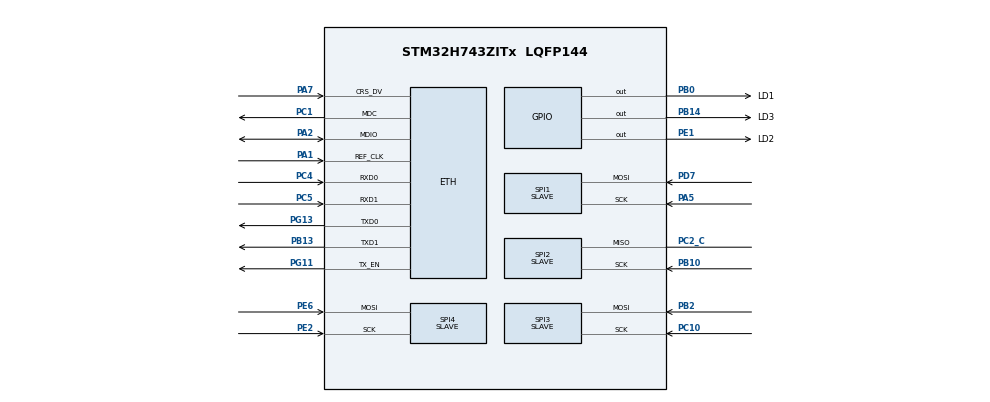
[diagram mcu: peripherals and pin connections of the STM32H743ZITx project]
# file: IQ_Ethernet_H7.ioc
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Mcu.Family=STM32H7
PD7.Mode=RX_Only_Simplex_Unidirect_Slave
LWIP0.BSP.STBoard=false
RCC.CortexFreq_Value=480000000
SPI3.Direction=SPI_DIRECTION_2LINES_RXONLY
SPI4.VirtualType=VM_SLAVE
SPI3.VirtualType=VM_SLAVE
SPI1.VirtualType=VM_SLAVE
SPI2.VirtualType=VM_SLAVE
PB10.Mode=Simplex_Bidirectional_Slave
RCC.HPRE=RCC_HCLK_DIV2
PH0-OSC_IN\ (PH0).Signal=RCC_OSC_IN
RCC.PLL2_VCI_Range-AdvancedSettings=RCC_PLL2VCIRANGE_0
PC10.Signal=SPI3_SCK
PB14.GPIO_Label=LD3
CORTEX_M7.TypeExtField-Cortex_Memory_Protection_Unit_Region0_Settings=MPU_TEX_LEVEL1
RCC.PLLFRACN=0
SPI4.Direction=SPI_DIRECTION_2LINES_RXONLY
PB0.GPIO_Label=LD1
RCC.PLL2FRACN=0
PC5.Mode=RMII
PB13.Signal=ETH_TXD1
PG13.Signal=ETH_TXD0
PG11.Signal=ETH_TX_EN
RCC.SYSCLKSource=RCC_SYSCLKSOURCE_PLLCLK
ProjectManager.StackSize=0x400
LWIP.NETMASK_ADDRESS=255.255.255.000
RCC.SPI123CLockSelection=RCC_SPI123CLKSOURCE_PLL2
CORTEX_M7.Enable-Cortex_Memory_Protection_Unit_Region0_Settings=MPU_REGION_ENABLE
SPI4.Mode=SPI_MODE_SLAVE
SPI1.Direction=SPI_DIRECTION_2LINES_RXONLY
RCC.HCLKFreq_Value=240000000
PE2.Mode=RX_Only_Simplex_Unidirect_Slave
PE1.Signal=GPIO_Output
PC2_C.Signal=SPI2_MISO
SPI3.DataSize=SPI_DATASIZE_8BIT
LWIP.LWIP_RAM_HEAP_POINTER=0x30002000
PH1-OSC_OUT\ (PH1).Mode=HSE-External-Oscillator
PB2.Signal=SPI3_MOSI
RCC.DIVM3=25
RCC.DIVM2=2
RCC.DIVM1=5
LWIP.MEM_SIZE=10*1024
RCC.PLL1_VCI_Range-AdvancedSettings=RCC_PLL1VCIRANGE_0
SPI1.DataSize=SPI_DATASIZE_8BIT
PE2.Signal=SPI4_SCK
PG13.Mode=RMII
RCC.PLL2_VCO_SEL-AdvancedSettings=RCC_PLL2VCOMEDIUM
LWIP0.BSP.solution=LAN8742
CORTEX_M7.DisableExec-Cortex_Memory_Protection_Unit_Region0_Settings=MPU_INSTRUCTION_ACCESS_DISABLE
RCC.APB3Freq_Value=120000000
LWIP0.BSP.component=LAN8742
Mcu.Package=LQFP144
SPI2.Mode=SPI_MODE_SLAVE
RCC.PLL3FRACN=0
RCC.D1PPRE=RCC_APB3_DIV2
SPI3.Mode=SPI_MODE_SLAVE
SPI2.CLKPhase=SPI_PHASE_2EDGE
RCC.APB4Freq_Value=120000000
ETH.RxBuffAddress=0x30000100
SPI2.Direction=SPI_DIRECTION_1LINE
PC5.Signal=ETH_RXD1
PB13.Mode=RMII
PH0-OSC_IN\ (PH0).Mode=HSE-External-Oscillator
PC4.Mode=RMII
LWIP.IP_ADDRESS=192.168.000.015
PA5.Mode=RX_Only_Simplex_Unidirect_Slave
RCC.PLLSourceVirtual=RCC_PLLSOURCE_HSE
CORTEX_M7.CPU_ICache=Enabled
PA7.Mode=RMII
LWIP0.BSP.i2caddr=0
SPI4.DataSize=SPI_DATASIZE_8BIT
PC4.Signal=ETH_RXD0
PC10.Mode=RX_Only_Simplex_Unidirect_Slave
PD7.Signal=SPI1_MOSI
RCC.D2PPRE2=RCC_APB2_DIV2
RCC.D2PPRE1=RCC_APB1_DIV2
SPI1.CLKPhase=SPI_PHASE_2EDGE
LWIP.LWIP_DHCP=0
PH1-OSC_OUT\ (PH1).Signal=RCC_OSC_OUT
LWIP.GATEWAY_ADDRESS=192.168.000.001
VP_LWIP_VS_Enabled.Mode=Enabled
CORTEX_M7.MPU_Control=MPU_PRIVILEGED_DEFAULT
ProjectManager.TargetToolchain=STM32CubeIDE
RCC.DIVN3=130
RCC.DIVN2=12
RCC.DIVN1=192
PC2_C.Mode=Simplex_Bidirectional_Slave
CORTEX_M7.BaseAddress-Cortex_Memory_Protection_Unit_Region0_Settings=0x30000000
LWIP0.BSP.instance=LAN8742
RCC.USBFreq_Value=480000000
LWIP0.BSP.api=BSP_COMPONENT_DRIVER
PA1.Signal=ETH_REF_CLK
PB10.Signal=SPI2_SCK
PB14.Signal=GPIO_Output
PA5.Signal=SPI1_SCK
board=custom
SPI3.CLKPhase=SPI_PHASE_2EDGE
PE1.GPIO_Label=LD2
RCC.APB2Freq_Value=120000000
PA1.Mode=RMII
PE6.Mode=RX_Only_Simplex_Unidirect_Slave
SPI1.Mode=SPI_MODE_SLAVE
CORTEX_M7.IsShareable-Cortex_Memory_Protection_Unit_Region0_Settings=MPU_ACCESS_SHAREABLE
RCC.ADCFreq_Value=75000000
CORTEX_M7.AccessPermission-Cortex_Memory_Protection_Unit_Region0_Settings=MPU_REGION_FULL_ACCESS
PE6.Signal=SPI4_MOSI
Mcu.Name=STM32H743ZITx
CORTEX_M7.Size-Cortex_Memory_Protection_Unit_Region0_Settings=MPU_REGION_SIZE_32KB
PA2.Signal=ETH_MDIO
RCC.PLL3_VCO_SEL-AdvancedSettings=RCC_PLL3VCOMEDIUM
RCC.SYSCLKFreq_VALUE=480000000
ETH.MediaInterface=HAL_ETH_RMII_MODE
LWIP.BSP.number=1
PB2.Mode=RX_Only_Simplex_Unidirect_Slave
PG11.Mode=RMII
ProjectManager.HeapSize=0x200
LWIP.Version=v2.1.2_Cube
SPI4.CLKPhase=SPI_PHASE_2EDGE
NVIC.PriorityGroup=NVIC_PRIORITYGROUP_4
PA2.Mode=RMII
RCC.D3PPRE=RCC_APB4_DIV2
SPI2.DataSize=SPI_DATASIZE_8BIT
ETH.RxDescAddress=0x30000000
CORTEX_M7.CPU_DCache=Enabled
LWIP0.BSP.name=Driver_PHY
RCC.APB1Freq_Value=120000000
PB0.Signal=GPIO_Output
PC1.Signal=ETH_MDC
PC1.Mode=RMII
PA7.Signal=ETH_CRS_DV
ETH.TxDescAddress=0x30000080

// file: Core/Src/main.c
/* USER CODE BEGIN Header */
/**
  ******************************************************************************
  * @file           : main.c
  * @brief          : Main program body
  ******************************************************************************
  * @attention
  *
  * <h2><center>&copy; Copyright (c) 2022 STMicroelectronics.
  * All rights reserved.</center></h2>
  *
  * This software component is licensed by ST under BSD 3-Clause license,
  * the "License"; You may not use this file except in compliance with the
  * License. You may obtain a copy of the License at:
  *                        opensource.org/licenses/BSD-3-Clause
  *
  ******************************************************************************
  */
/* USER CODE END Header */
#include "main.h"
#include "lwip.h"

SPI_HandleTypeDef hspi1;
SPI_HandleTypeDef hspi2;
SPI_HandleTypeDef hspi3;
SPI_HandleTypeDef hspi4;

/* USER CODE BEGIN PV */
extern struct netif  gnetif;
/* USER CODE END PV */

void SystemClock_Config(void);
void PeriphCommonClock_Config(void);
static void MPU_Config(void);
static void MX_GPIO_Init(void);
static void MX_SPI1_Init(void);
static void MX_SPI2_Init(void);
static void MX_SPI3_Init(void);
static void MX_SPI4_Init(void);

int main(void)
{

  /* MPU Configuration--------------------------------------------------------*/
  MPU_Config();

  /* Enable I-Cache---------------------------------------------------------*/
  SCB_EnableICache();

  /* Enable D-Cache---------------------------------------------------------*/
  SCB_EnableDCache();

  /* MCU Configuration--------------------------------------------------------*/

  /* Reset of all peripherals, Initializes the Flash interface and the Systick. */
  HAL_Init();

  /* Configure the system clock */
  SystemClock_Config();

/* Configure the peripherals common clocks */
  PeriphCommonClock_Config();

  /* Initialize all configured peripherals */
  MX_GPIO_Init();
  MX_LWIP_Init();
  MX_SPI1_Init();
  MX_SPI2_Init();
  MX_SPI3_Init();
  MX_SPI4_Init();
  /* USER CODE BEGIN 2 */
  App_Init();
  App_Runtime();
  /* USER CODE END 2 */

  /* Infinite loop */
  /* USER CODE BEGIN WHILE */
  while (1)
  {
		ethernetif_input(&gnetif);
		sys_check_timeouts();
    /* USER CODE END WHILE */

  }
}

void SystemClock_Config(void)
{
  RCC_OscInitTypeDef RCC_OscInitStruct = {0};
  RCC_ClkInitTypeDef RCC_ClkInitStruct = {0};

  /** Supply configuration update enable
  */
  HAL_PWREx_ConfigSupply(PWR_LDO_SUPPLY);
  /** Configure the main internal regulator output voltage
  */
  __HAL_PWR_VOLTAGESCALING_CONFIG(PWR_REGULATOR_VOLTAGE_SCALE0);

  while(!__HAL_PWR_GET_FLAG(PWR_FLAG_VOSRDY)) {}
  /** Macro to configure the PLL clock source
  */
  __HAL_RCC_PLL_PLLSOURCE_CONFIG(RCC_PLLSOURCE_HSE);
  /** Initializes the RCC Oscillators according to the specified parameters
  * in the RCC_OscInitTypeDef structure.
  */
  RCC_OscInitStruct.OscillatorType = RCC_OSCILLATORTYPE_HSE;
  RCC_OscInitStruct.HSEState = RCC_HSE_ON;
  RCC_OscInitStruct.PLL.PLLState = RCC_PLL_ON;
  RCC_OscInitStruct.PLL.PLLSource = RCC_PLLSOURCE_HSE;
  RCC_OscInitStruct.PLL.PLLM = 5;
  RCC_OscInitStruct.PLL.PLLN = 192;
  RCC_OscInitStruct.PLL.PLLP = 2;
  RCC_OscInitStruct.PLL.PLLQ = 2;
  RCC_OscInitStruct.PLL.PLLR = 2;
  RCC_OscInitStruct.PLL.PLLRGE = RCC_PLL1VCIRANGE_2;
  RCC_OscInitStruct.PLL.PLLVCOSEL = RCC_PLL1VCOWIDE;
  RCC_OscInitStruct.PLL.PLLFRACN = 0;
  if (HAL_RCC_OscConfig(&RCC_OscInitStruct) != HAL_OK)
  {
    Error_Handler();
  }
  /** Initializes the CPU, AHB and APB buses clocks
  */
  RCC_ClkInitStruct.ClockType = RCC_CLOCKTYPE_HCLK|RCC_CLOCKTYPE_SYSCLK
                              |RCC_CLOCKTYPE_PCLK1|RCC_CLOCKTYPE_PCLK2
                              |RCC_CLOCKTYPE_D3PCLK1|RCC_CLOCKTYPE_D1PCLK1;
  RCC_ClkInitStruct.SYSCLKSource = RCC_SYSCLKSOURCE_PLLCLK;
  RCC_ClkInitStruct.SYSCLKDivider = RCC_SYSCLK_DIV1;
  RCC_ClkInitStruct.AHBCLKDivider = RCC_HCLK_DIV2;
  RCC_ClkInitStruct.APB3CLKDivider = RCC_APB3_DIV2;
  RCC_ClkInitStruct.APB1CLKDivider = RCC_APB1_DIV2;
  RCC_ClkInitStruct.APB2CLKDivider = RCC_APB2_DIV2;
  RCC_ClkInitStruct.APB4CLKDivider = RCC_APB4_DIV2;

  if (HAL_RCC_ClockConfig(&RCC_ClkInitStruct, FLASH_LATENCY_4) != HAL_OK)
  {
    Error_Handler();
  }
}

void PeriphCommonClock_Config(void)
{
  RCC_PeriphCLKInitTypeDef PeriphClkInitStruct = {0};

  /** Initializes the peripherals clock
  */
  PeriphClkInitStruct.PeriphClockSelection = RCC_PERIPHCLK_SPI3|RCC_PERIPHCLK_SPI2
                              |RCC_PERIPHCLK_SPI1;
  PeriphClkInitStruct.PLL2.PLL2M = 2;
  PeriphClkInitStruct.PLL2.PLL2N = 12;
  PeriphClkInitStruct.PLL2.PLL2P = 2;
  PeriphClkInitStruct.PLL2.PLL2Q = 2;
  PeriphClkInitStruct.PLL2.PLL2R = 2;
  PeriphClkInitStruct.PLL2.PLL2RGE = RCC_PLL2VCIRANGE_3;
  PeriphClkInitStruct.PLL2.PLL2VCOSEL = RCC_PLL2VCOMEDIUM;
  PeriphClkInitStruct.PLL2.PLL2FRACN = 0;
  PeriphClkInitStruct.Spi123ClockSelection = RCC_SPI123CLKSOURCE_PLL2;
  if (HAL_RCCEx_PeriphCLKConfig(&PeriphClkInitStruct) != HAL_OK)
  {
    Error_Handler();
  }
}

static void MX_SPI1_Init(void)
{

  /* SPI1 parameter configuration*/
  hspi1.Instance = SPI1;
  hspi1.Init.Mode = SPI_MODE_SLAVE;
  hspi1.Init.Direction = SPI_DIRECTION_2LINES_RXONLY;
  hspi1.Init.DataSize = SPI_DATASIZE_8BIT;
  hspi1.Init.CLKPolarity = SPI_POLARITY_LOW;
  hspi1.Init.CLKPhase = SPI_PHASE_2EDGE;
  hspi1.Init.NSS = SPI_NSS_SOFT;
  hspi1.Init.FirstBit = SPI_FIRSTBIT_MSB;
  hspi1.Init.TIMode = SPI_TIMODE_DISABLE;
  hspi1.Init.CRCCalculation = SPI_CRCCALCULATION_DISABLE;
  hspi1.Init.CRCPolynomial = 0x0;
  hspi1.Init.NSSPMode = SPI_NSS_PULSE_DISABLE;
  hspi1.Init.NSSPolarity = SPI_NSS_POLARITY_LOW;
  hspi1.Init.FifoThreshold = SPI_FIFO_THRESHOLD_01DATA;
  hspi1.Init.TxCRCInitializationPattern = SPI_CRC_INITIALIZATION_ALL_ZERO_PATTERN;
  hspi1.Init.RxCRCInitializationPattern = SPI_CRC_INITIALIZATION_ALL_ZERO_PATTERN;
  hspi1.Init.MasterSSIdleness = SPI_MASTER_SS_IDLENESS_00CYCLE;
  hspi1.Init.MasterInterDataIdleness = SPI_MASTER_INTERDATA_IDLENESS_00CYCLE;
  hspi1.Init.MasterReceiverAutoSusp = SPI_MASTER_RX_AUTOSUSP_DISABLE;
  hspi1.Init.MasterKeepIOState = SPI_MASTER_KEEP_IO_STATE_DISABLE;
  hspi1.Init.IOSwap = SPI_IO_SWAP_DISABLE;
  if (HAL_SPI_Init(&hspi1) != HAL_OK)
  {
    Error_Handler();
  }

}

static void MX_SPI2_Init(void)
{

  /* SPI2 parameter configuration*/
  hspi2.Instance = SPI2;
  hspi2.Init.Mode = SPI_MODE_SLAVE;
  hspi2.Init.Direction = SPI_DIRECTION_1LINE;
  hspi2.Init.DataSize = SPI_DATASIZE_8BIT;
  hspi2.Init.CLKPolarity = SPI_POLARITY_LOW;
  hspi2.Init.CLKPhase = SPI_PHASE_2EDGE;
  hspi2.Init.NSS = SPI_NSS_SOFT;
  hspi2.Init.FirstBit = SPI_FIRSTBIT_MSB;
  hspi2.Init.TIMode = SPI_TIMODE_DISABLE;
  hspi2.Init.CRCCalculation = SPI_CRCCALCULATION_DISABLE;
  hspi2.Init.CRCPolynomial = 0x0;
  hspi2.Init.NSSPMode = SPI_NSS_PULSE_DISABLE;
  hspi2.Init.NSSPolarity = SPI_NSS_POLARITY_LOW;
  hspi2.Init.FifoThreshold = SPI_FIFO_THRESHOLD_01DATA;
  hspi2.Init.TxCRCInitializationPattern = SPI_CRC_INITIALIZATION_ALL_ZERO_PATTERN;
  hspi2.Init.RxCRCInitializationPattern = SPI_CRC_INITIALIZATION_ALL_ZERO_PATTERN;
  hspi2.Init.MasterSSIdleness = SPI_MASTER_SS_IDLENESS_00CYCLE;
  hspi2.Init.MasterInterDataIdleness = SPI_MASTER_INTERDATA_IDLENESS_00CYCLE;
  hspi2.Init.MasterReceiverAutoSusp = SPI_MASTER_RX_AUTOSUSP_DISABLE;
  hspi2.Init.MasterKeepIOState = SPI_MASTER_KEEP_IO_STATE_DISABLE;
  hspi2.Init.IOSwap = SPI_IO_SWAP_DISABLE;
  if (HAL_SPI_Init(&hspi2) != HAL_OK)
  {
    Error_Handler();
  }

}

static void MX_SPI3_Init(void)
{

  /* SPI3 parameter configuration*/
  hspi3.Instance = SPI3;
  hspi3.Init.Mode = SPI_MODE_SLAVE;
  hspi3.Init.Direction = SPI_DIRECTION_2LINES_RXONLY;
  hspi3.Init.DataSize = SPI_DATASIZE_8BIT;
  hspi3.Init.CLKPolarity = SPI_POLARITY_LOW;
  hspi3.Init.CLKPhase = SPI_PHASE_2EDGE;
  hspi3.Init.NSS = SPI_NSS_SOFT;
  hspi3.Init.FirstBit = SPI_FIRSTBIT_MSB;
  hspi3.Init.TIMode = SPI_TIMODE_DISABLE;
  hspi3.Init.CRCCalculation = SPI_CRCCALCULATION_DISABLE;
  hspi3.Init.CRCPolynomial = 0x0;
  hspi3.Init.NSSPMode = SPI_NSS_PULSE_DISABLE;
  hspi3.Init.NSSPolarity = SPI_NSS_POLARITY_LOW;
  hspi3.Init.FifoThreshold = SPI_FIFO_THRESHOLD_01DATA;
  hspi3.Init.TxCRCInitializationPattern = SPI_CRC_INITIALIZATION_ALL_ZERO_PATTERN;
  hspi3.Init.RxCRCInitializationPattern = SPI_CRC_INITIALIZATION_ALL_ZERO_PATTERN;
  hspi3.Init.MasterSSIdleness = SPI_MASTER_SS_IDLENESS_00CYCLE;
  hspi3.Init.MasterInterDataIdleness = SPI_MASTER_INTERDATA_IDLENESS_00CYCLE;
  hspi3.Init.MasterReceiverAutoSusp = SPI_MASTER_RX_AUTOSUSP_DISABLE;
  hspi3.Init.MasterKeepIOState = SPI_MASTER_KEEP_IO_STATE_DISABLE;
  hspi3.Init.IOSwap = SPI_IO_SWAP_DISABLE;
  if (HAL_SPI_Init(&hspi3) != HAL_OK)
  {
    Error_Handler();
  }

}

static void MX_SPI4_Init(void)
{

  /* SPI4 parameter configuration*/
  hspi4.Instance = SPI4;
  hspi4.Init.Mode = SPI_MODE_SLAVE;
  hspi4.Init.Direction = SPI_DIRECTION_2LINES_RXONLY;
  hspi4.Init.DataSize = SPI_DATASIZE_8BIT;
  hspi4.Init.CLKPolarity = SPI_POLARITY_LOW;
  hspi4.Init.CLKPhase = SPI_PHASE_2EDGE;
  hspi4.Init.NSS = SPI_NSS_SOFT;
  hspi4.Init.FirstBit = SPI_FIRSTBIT_MSB;
  hspi4.Init.TIMode = SPI_TIMODE_DISABLE;
  hspi4.Init.CRCCalculation = SPI_CRCCALCULATION_DISABLE;
  hspi4.Init.CRCPolynomial = 0x0;
  hspi4.Init.NSSPMode = SPI_NSS_PULSE_DISABLE;
  hspi4.Init.NSSPolarity = SPI_NSS_POLARITY_LOW;
  hspi4.Init.FifoThreshold = SPI_FIFO_THRESHOLD_01DATA;
  hspi4.Init.TxCRCInitializationPattern = SPI_CRC_INITIALIZATION_ALL_ZERO_PATTERN;
  hspi4.Init.RxCRCInitializationPattern = SPI_CRC_INITIALIZATION_ALL_ZERO_PATTERN;
  hspi4.Init.MasterSSIdleness = SPI_MASTER_SS_IDLENESS_00CYCLE;
  hspi4.Init.MasterInterDataIdleness = SPI_MASTER_INTERDATA_IDLENESS_00CYCLE;
  hspi4.Init.MasterReceiverAutoSusp = SPI_MASTER_RX_AUTOSUSP_DISABLE;
  hspi4.Init.MasterKeepIOState = SPI_MASTER_KEEP_IO_STATE_DISABLE;
  hspi4.Init.IOSwap = SPI_IO_SWAP_DISABLE;
  if (HAL_SPI_Init(&hspi4) != HAL_OK)
  {
    Error_Handler();
  }

}

static void MX_GPIO_Init(void)
{
  GPIO_InitTypeDef GPIO_InitStruct = {0};

  /* GPIO Ports Clock Enable */
  __HAL_RCC_GPIOE_CLK_ENABLE();
  __HAL_RCC_GPIOH_CLK_ENABLE();
  __HAL_RCC_GPIOC_CLK_ENABLE();
  __HAL_RCC_GPIOA_CLK_ENABLE();
  __HAL_RCC_GPIOB_CLK_ENABLE();
  __HAL_RCC_GPIOD_CLK_ENABLE();
  __HAL_RCC_GPIOG_CLK_ENABLE();

  /*Configure GPIO pin Output Level */
  HAL_GPIO_WritePin(GPIOB, LD1_Pin|LD3_Pin, GPIO_PIN_RESET);

  /*Configure GPIO pin Output Level */
  HAL_GPIO_WritePin(LD2_GPIO_Port, LD2_Pin, GPIO_PIN_RESET);

  /*Configure GPIO pins : LD1_Pin LD3_Pin */
  GPIO_InitStruct.Pin = LD1_Pin|LD3_Pin;
  GPIO_InitStruct.Mode = GPIO_MODE_OUTPUT_PP;
  GPIO_InitStruct.Pull = GPIO_NOPULL;
  GPIO_InitStruct.Speed = GPIO_SPEED_FREQ_LOW;
  HAL_GPIO_Init(GPIOB, &GPIO_InitStruct);

  /*Configure GPIO pin : LD2_Pin */
  GPIO_InitStruct.Pin = LD2_Pin;
  GPIO_InitStruct.Mode = GPIO_MODE_OUTPUT_PP;
  GPIO_InitStruct.Pull = GPIO_NOPULL;
  GPIO_InitStruct.Speed = GPIO_SPEED_FREQ_LOW;
  HAL_GPIO_Init(LD2_GPIO_Port, &GPIO_InitStruct);

}

/* MPU Configuration */

void MPU_Config(void)
{
  MPU_Region_InitTypeDef MPU_InitStruct = {0};

  /* Disables the MPU */
  HAL_MPU_Disable();
  /** Initializes and configures the Region and the memory to be protected
  */
  MPU_InitStruct.Enable = MPU_REGION_ENABLE;
  MPU_InitStruct.Number = MPU_REGION_NUMBER0;
  MPU_InitStruct.BaseAddress = 0x30000000;
  MPU_InitStruct.Size = MPU_REGION_SIZE_32KB;
  MPU_InitStruct.SubRegionDisable = 0x0;
  MPU_InitStruct.TypeExtField = MPU_TEX_LEVEL1;
  MPU_InitStruct.AccessPermission = MPU_REGION_FULL_ACCESS;
  MPU_InitStruct.DisableExec = MPU_INSTRUCTION_ACCESS_DISABLE;
  MPU_InitStruct.IsShareable = MPU_ACCESS_SHAREABLE;
  MPU_InitStruct.IsCacheable = MPU_ACCESS_NOT_CACHEABLE;
  MPU_InitStruct.IsBufferable = MPU_ACCESS_NOT_BUFFERABLE;

  HAL_MPU_ConfigRegion(&MPU_InitStruct);
  /* Enables the MPU */
  HAL_MPU_Enable(MPU_PRIVILEGED_DEFAULT);

}

void Error_Handler(void)
{
  __disable_irq();
  while (1)
  {
  }
}

/************************ (C) COPYRIGHT STMicroelectronics *****END OF FILE****/
